# cslr_tmr register map
Vendor: Texas Instruments
Peripheral module from a debugger description file (folder c6472).
Registers are 32-bit, access not given, reset 0x0 unless marked. A register's access mark holds for its fields unless they carry their own. Offsets are as the file gives them; lines under a group give offsets from that group; [hi:lo] are bit positions; {n}, {i} and the like mark numbered series; 'fields as' and 'values as' point back to an identical list; <NAME> marks a mode.

## TMR — Timer
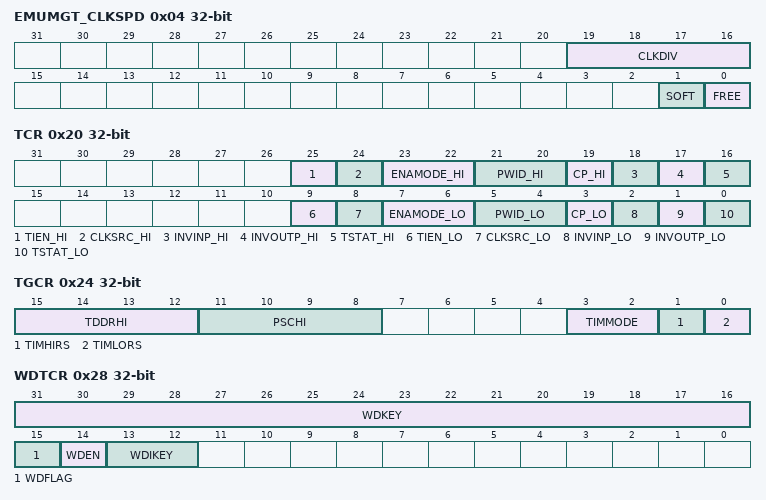
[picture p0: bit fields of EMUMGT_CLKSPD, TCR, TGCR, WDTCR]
0x04 EMUMGT_CLKSPD — Emulation Management/ Clock Speed Register
  [19:16] CLKDIV ro — Defines the internal clock frequency divider ratio for the timer
  [1] SOFT rw — Determines emulation mode functionality of the timer When the FREE bit is cleared, the SOFT bit selects the timer mode 0: The timer stops immediately 1: The timer stops when the counter increments and reaches the value in the timer period register
  [0] FREE rw — Determines emulation mode functionality of the timer When the FREE bit is cleared, the SOFT bit selects the timer mode 0: The Soft bit selects the timer mode 1: The timer runs free regardless of the soft bit
0x10 TIMLO rw — Timer Counter Low Register
  [31:0] TIMLO — In the GP timer mode and watchdog mode, the 64-bit up counter is formed with TIMLO and TIMHI, and increments when it is enabled to count. This register is set to 0h at reset. In the "dual 32-bit timer" chained mode, it acts as a 32-bit timer counter and increments by 1 at every pre-scalar output clock cycle( i.e TIMHI). When the timer counter matches the timer period, a maskable interrupt TINTLO, a timer EDMA event TEVTLO, and an output signal are generated. In the dual 32-bit timer unchained mode, it can be used as an independent 32-bit timer.When the timer counter matches the timer period, a maskable interrupt TINTLO, a timer EDMA event TEVTLO, and an output signal are generated.
0x14 TIMHI rw — Timer Counter High Register
  [31:0] TIMHI — In the GP timer mode and watchdog mode, the 64-bit up counter is formed with TIMLO and TIMHI, and increments when it is enabled to count. This register is set to 0h at reset In the dual 32-bit timer chained mode, it acts as a 32-bit pre-scalar to TIMLO. When the timer is enabled, the prescale counter starts incrementing by 1 at every timer input clock cycle. One cycle after the prescale counter matches the prescale period, a clock signal is generated and the prescale counter register is reset to 0 In the dual 32-bit unchained mode, it can be used as an independent 32-bit timer and a 4-bit pre-scalar (it is formed by the timer divide down ratio bits and the pre-scalar counter bits) must be clocked by internal clock.One cycle after the prescale counter matches the prescale period, a clock signal is generated for the 32-bit timer When the timer counter matches the timer period, a maskable interrupt TINTHI, a timer EDMA event TEVTHI are generated.
0x18 PRDLO rw — Timer Period Low Register
  [31:0] PRDLO — In a 64-bit general-purpose timer mode and watchdog mode, this is used in conjunction with the PRDHI register bits to form a 64-bit period register and to define the number of timer input clock cycles to count. In a 32-bit dual timer chained mode, it can be used as a 32-bit period register to define the number of timer input clock cycles to count. In the 32-bit dual timer unchained mode, it can be used as 32-bit period register to define the number of timer input clock cycles to count.
0x1C PRDHI rw — Timer Period High Register
  [31:0] PRDHI — In a 64-bit general-purpose timer mode and watchdog mode, this is used in conjunction with the PRDLO register bits to form a 64-bit period register and to define the number of timer input clock cycles to count. In a 32-bit dual timer chained mode, it can be used as a 32-bit pre-scalar period register. TIMLO is clocked by this pre-scalar output clock. In the 32-bit dual timer unchained mode, it can be used as 32-bit period register to define the number of timer input clock cycles to count.
0x20 TCR — Timer Control Register
  [25] TIEN_HI rw — TIEN determines if the timer clock is gated by the timer input Applicable only when CLKSRC = 0 0: Timer clock is not gated by the timer input 1: Timer clock is gated by a high state of the timer input TINP synchronized with Internal clock. Timer starts counting when TINP transitions from low to high. Timer stops counting when TINP transitions from high to low Note that the TCRHI is applicable only when the timer is configured in unchained dual 32-bit timer mode (TGCR[3:2]=[01])
  [24] CLKSRC_HI rw — CLKSRC determines the selected clock source for the timer 0: Internal clock 1: Timer Input pin Note that the TCRHI is applicable only when the timer is configured in unchained dual 32-bit timer mode (TGCR[3:2]=[01])
  [23:22] ENAMODE_HI rw — Enabling mode determines the enabling modes of the timer 00: The timer is disabled (not counting) and maintains current value 01: The timer is enabled one time. The timer stops after the counter reaches the period 10: The timer is enabled continuously, TIMx increments until the timer counter matches the period, resets the timer counter to zero on the cycle after matching and continues 11: Reserved. Note that the TCRHI is applicable only when the timer is configured in unchained dual 32-bit timer mode (TGCR[3:2]=[01])
  [21:20] PWID_HI rw — Pulse width Only used in pulse mode (C/P_=0) by the timer controls the timer output 00: TSTATx goes inactive one timer clock cycle after the timer counter reaches the period 01: TSTATx goes inactive two timer clock cycles after the timer counter reaches the period 10: TSTATx goes inactive three timer clock cycles after the timer counter reaches the period 11: TSTATx goes inactive four timer clock cycles after the timer counter reaches the period Note that the TCRHI is applicable only when the timer is configured in unchained dual 32-bit timer mode (TGCR[3:2]=[01])
  [19] CP_HI rw — Clock/Pulse mode for timer output Not applicable in WD mode (TIMMODE[1:0] = 10) 0: Pulse mode. TSTATx is active one timer clock after the timer counter reaches the timer period. PWID[1:0] determines when it goes inactive 1: Clock mode. TIN/TOUT is a 50% duty cycle signal, it toggles high->low or low->high when timer counter reaches zero Note that the TCRHI is applicable only when the timer is configured in unchained dual 32-bit timer mode (TGCR[3:2]=[01])
  [18] INVINP_HI rw — Timer input inverter control Only affects operation if CLKSRC = 1 0: Uninverted timer input drives timer 1: Inverted timer input drives timer Note that the TCRHI is applicable only when the timer is configured in unchained dual 32-bit timer mode (TGCR[3:2]=[01])
  [17] INVOUTP_HI rw — Timer output inverter control 0: Uninverted timer output 1: Inverted timer output Note that the TCRHI is applicable only when the timer is configured in unchained dual 32-bit timer mode (TGCR[3:2]=[01])
  [16] TSTAT_HI ro — Timer status Value of timer output. TSTATx drives the timer output pin when the pin is used as a timer pin (instead of a GPIO) and maybe inverted by setting INVOUTP = 1 Note that the TCRHI is applicable only when the timer is configured in unchained dual 32-bit timer mode (TGCR[3:2]=[01])
  [9] TIEN_LO rw — TIEN determines if the timer clock is gated by the timer input Applicable only when CLKSRC = 0 0: Timer clock is not gated by the timer input 1: Timer clock is gated by a high state of the timer input TINP synchronized with Internal clock. Timer starts counting when TINP transitions from low to high. Timer stops counting when TINP transitions from high to low
  [8] CLKSRC_LO rw — CLKSRC determines the selected clock source for the timer 0: Internal clock 1: Timer Input pin
  [7:6] ENAMODE_LO rw — Enabling mode determines the enabling modes of the timer 00: The timer is disabled (not counting) and maintains current value 01: The timer is enabled one time. The timer stops after the counter reaches the period 10: The timer is enabled continuously, TIMx increments until the timer counter matches the period, resets the timer counter to zero on the cycle after matching and continues 11: Reserved.
  [5:4] PWID_LO rw — Pulse width Only used in pulse mode (C/P_=0) by the timer controls the timer output 00: TSTATx goes inactive one timer clock cycle after the timer counter reaches the period 01: TSTATx goes inactive two timer clock cycles after the timer counter reaches the period 10: TSTATx goes inactive three timer clock cycles after the timer counter reaches the period 11: TSTATx goes inactive four timer clock cycles after the timer counter reaches the period
  [3] CP_LO rw — Clock/Pulse mode for timer output Not applicable in WD mode (TIMMODE[1:0] = 10) 0: Pulse mode. TSTATx is active one timer clock after the timer counter reaches the timer period. PWID[1:0] determines when it goes inactive 1: Clock mode. TIN/TOUT is a 50% duty cycle signal, it toggles high->low or low->high when timer counter reaches zero
  [2] INVINP_LO rw — Timer input inverter control Only affects operation if CLKSRC = 1 0: Uninverted timer input drives timer 1: Inverted timer input drives timer
  [1] INVOUTP_LO rw — Timer output inverter control 0: Uninverted timer output 1: Inverted timer output
  [0] TSTAT_LO ro — Timer status Value of timer output. TSTATx drives the timer output pin when the pin is used as a timer pin (instead of a GPIO) and maybe inverted by setting INVOUTP = 1
0x24 TGCR — Timer Global Control Register
  [15:12] TDDRHI rw — Timer linear divide-down ratio specifies the timer divide-down ratio for the timer TIMHI When the timer enabled, the TDDRHI increments every timer clock. The TIMHI counter increments on the cycle after the TDDRHI matches the PSCHI. The TDDRHI resets to zero and continues. When the TIMHI matches the PRDHI, the TIMHI stops if it enabled one time or TIMHI reset to zero on the cycle after matching the PRDHI and TIMHI continues if the timer enabled continuously
  [11:8] PSCHI rw — TIMHI pre-scalar counter specifies the count for TIMHI
  [3:2] TIMMODE rw — TIMMODE determines timer mode 00: The timer is in 64-bit GP timer mode 01: The timer is in dual 32-bit timer, unchained mode 10: The timer is in 64-bit Watchdog timer mode 11: The timer is in dual 32-bit timer, chained mode
  [1] TIMHIRS rw — TIMHI reset 0: Timer TIMHI is in reset 1: Timer TIMHI is not in reset. TIMHI can be used as a 32-bit timer.Note that in order for the timer functions properly in 64-bit timer mode both TIMHIRS_ and TIMLORS_ must be set to '1'. Changing this bit does not affect the timer if the timer is in the watchdog active state.
  [0] TIMLORS rw — TIMLO reset 0: Timer TIMLO is in reset, TOUT(P) is tri-stated 1: Timer TIMLO is not in reset. TIMLO can be used as a 32-bit timer.Note that in order for the timer functions properly in 64-bit timer mode both TIMHIRS_ and TIMLORS_ must be set to '1'. Changing this bit does not affect the timer if the timer is in the watchdog active state
0x28 WDTCR — Watchdog Timer Control Register
  [31:16] WDKEY rw — 16-bit watchdog reset key Only the sequence of an A5C6h followed by a DA7Eh services the watchdog. Not applicable in regular timer mode
    0xA5C6=CMD1 (Watchdog key); 0xDA7E=CMD2 (Watchdog key)
  [15] WDFLAG rw — Watchdog flag bit This bit can be cleared by enabling the watchdog timer, by device reset and by being written with '1'. It is set by a watchdog time-out 0: No watchdog timeout occurred 1: Watchdog timeout occurred
  [14] WDEN rw — Watchdog timer enable bit 0: Watchdog disable, watchdog output pin is disconnected from the watchdog timeout event. The timer is in regular timer mode 1: Watchdog enable. TIN/TOUT pin is an output and connected to the watchdog timeout event, can be disabled by watchdog timeout or reset
  [13:12] WDIKEY rw — 2-bit watchdog IDLE enable key Only the sequence of a 01b followed by a 10b enable the watchdog to go in IDLE mode. Not applicable in regular timer mode A write of 00b to the WDIKEY will disallow the watchdog timer goes into the IDLE mode
